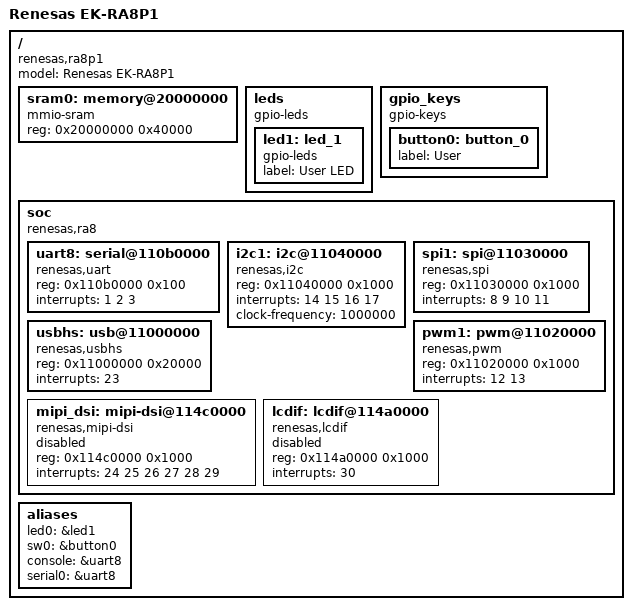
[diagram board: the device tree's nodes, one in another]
// EK-RA8P1 Device Tree
// EK-RA8P1 设备树
//
// 基于 Zephyr 的 ek_ra8p1 设备树配置移植

/dts-v1/;

/ {
    model = "Renesas EK-RA8P1";
    compatible = "renesas,ra8p1", "renesas,ra8";

    sram0: memory@20000000 {
        device_type = "memory";
        compatible = "mmio-sram";
        reg = <0x20000000 0x40000>;
    };

    leds {
        compatible = "gpio-leds";

        led1: led_1 {
            compatible = "gpio-leds";
            label = "User LED";
        };
    };

    gpio_keys {
        compatible = "gpio-keys";

        button0: button_0 {
            label = "User";
            status = "okay";
        };
    };

    soc {
        #address-cells = <1>;
        #size-cells = <1>;
        compatible = "renesas,ra8";
        ranges;

        uart8: serial@110b0000 {
            compatible = "renesas,uart";
            reg = <0x110b0000 0x100>;
            interrupts = <1 2 3>;
            status = "okay";
        };

        i2c1: i2c@11040000 {
            compatible = "renesas,i2c";
            reg = <0x11040000 0x1000>;
            interrupts = <14 15 16 17>;
            clock-frequency = <1000000>;
            status = "okay";
        };

        spi1: spi@11030000 {
            compatible = "renesas,spi";
            reg = <0x11030000 0x1000>;
            interrupts = <8 9 10 11>;
            status = "okay";
        };

        usbhs: usb@11000000 {
            compatible = "renesas,usbhs";
            reg = <0x11000000 0x20000>;
            interrupts = <23>;
            status = "okay";
        };

        pwm1: pwm@11020000 {
            compatible = "renesas,pwm";
            reg = <0x11020000 0x1000>;
            interrupts = <12 13>;
            status = "okay";
        };

        mipi_dsi: mipi-dsi@114c0000 {
            compatible = "renesas,mipi-dsi";
            reg = <0x114c0000 0x1000>;
            interrupts = <24 25 26 27 28 29>;
            status = "disabled";
        };

        lcdif: lcdif@114a0000 {
            compatible = "renesas,lcdif";
            reg = <0x114a0000 0x1000>;
            interrupts = <30>;
            status = "disabled";
        };
    };

    aliases {
        led0 = &led1;
        sw0 = &button0;
        console = &uart8;
        serial0 = &uart8;
    };
};
